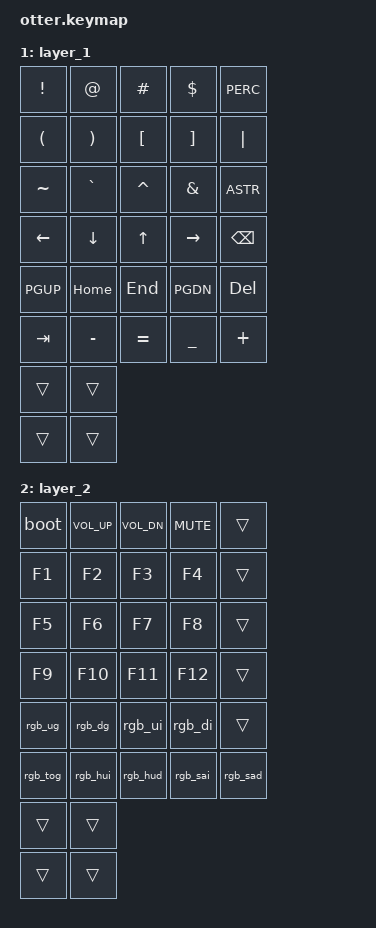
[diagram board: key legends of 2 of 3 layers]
/*
 * Copyright (c) 2022 The ZMK Contributors
 *
 * SPDX-License-Identifier: MIT
 */

/ {
  keymap {
    compatible = "zmk,keymap";

    base_layer {
      bindings = <
        &kp Q       &kp W       &kp F         &kp P       &kp G
        &kp A       &kp R       &sk S LCTRL    &sk T LSHFT &kp D
        &kp Z       &kp X       &kp C         &kp V       &kp B

        &kp J       &kp L       &kp U         &kp Y       &kp SEMI
        &kp M       &kp N       &sk E LCTRL    &sk N LSHFT &kp O
        &kp DOT     &kp COMMA   &kp K         &kp H       &kp SLASH

        &mo 1       &kp SPACE   // Left thumb keys: MO(1), SPACE
        &kp ENTER   &mo 2       // Right thumb keys: ENTER, MO(2)
      >;
    };

    layer_1 {
      bindings = <
        &kp EXCL    &kp AT      &kp HASH      &kp DLLR    &kp PERC
        &kp LPAR    &kp RPAR    &kp LBKT      &kp RBKT    &kp PIPE
        &kp TILDE   &kp GRAVE   &kp CARET     &kp AMPS    &kp ASTR

        &kp LEFT    &kp DOWN    &kp UP        &kp RIGHT   &kp BSPC
        &kp PGUP    &kp HOME    &kp END       &kp PGDN    &kp DEL
        &kp TAB     &kp MINUS   &kp EQUAL     &kp UNDER   &kp PLUS

        &trans      &trans
        &trans      &trans
      >;
    };

    layer_2 {
      bindings = <
        &boot       &kp C_VOL_UP &kp C_VOL_DN &kp MUTE    &trans
        &kp F1      &kp F2       &kp F3       &kp F4      &trans
        &kp F5      &kp F6       &kp F7       &kp F8      &trans

        &kp F9      &kp F10      &kp F11      &kp F12     &trans
        &rgb_ug     &rgb_dg      &rgb_ui      &rgb_di     &trans
        &rgb_tog    &rgb_hui     &rgb_hud     &rgb_sai    &rgb_sad

        &trans      &trans
        &trans      &trans
      >;
    };
  };
};
